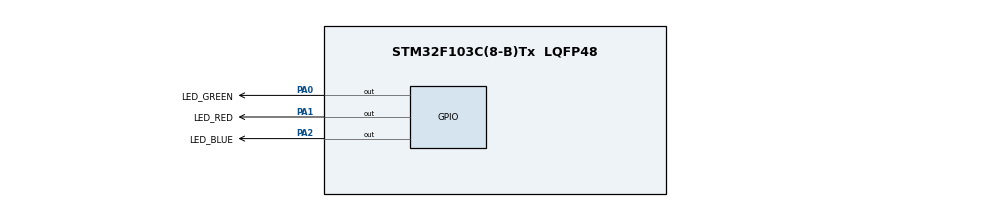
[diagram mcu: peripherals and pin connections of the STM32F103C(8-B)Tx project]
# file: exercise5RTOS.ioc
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FREERTOS.Tasks01=defaultTask,0,128,StartDefaultTask,Default,NULL,Dynamic,NULL,NULL
Mcu.Family=STM32F1
Mcu.Name=STM32F103C(8-B)Tx
Mcu.Package=LQFP48
NVIC.PriorityGroup=NVIC_PRIORITYGROUP_4
PA0-WKUP.GPIO_Label=LED_GREEN
PA0-WKUP.Signal=GPIO_Output
PA1.GPIO_Label=LED_RED
PA1.Signal=GPIO_Output
PA13.Mode=Serial_Wire
PA13.Signal=SYS_JTMS-SWDIO
PA14.Mode=Serial_Wire
PA14.Signal=SYS_JTCK-SWCLK
PA2.GPIO_Label=LED_BLUE
PA2.Signal=GPIO_Output
PD0-OSC_IN.Mode=HSE-External-Oscillator
PD0-OSC_IN.Signal=RCC_OSC_IN
PD1-OSC_OUT.Mode=HSE-External-Oscillator
PD1-OSC_OUT.Signal=RCC_OSC_OUT
ProjectManager.HeapSize=0x200
ProjectManager.StackSize=0x400
ProjectManager.TargetToolchain=STM32CubeIDE
RCC.APB1Freq_Value=8000000
RCC.APB2Freq_Value=8000000
VP_FREERTOS_VS_CMSIS_V1.Mode=CMSIS_V1
board=custom

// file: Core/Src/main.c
/* USER CODE BEGIN Header */
/**
  ******************************************************************************
  * @file           : main.c
  * @brief          : Main program body
  ******************************************************************************
  * @attention
  *
  * Copyright (c) 2024 STMicroelectronics.
  * All rights reserved.
  *
  * This software is licensed under terms that can be found in the LICENSE file
  * in the root directory of this software component.
  * If no LICENSE file comes with this software, it is provided AS-IS.
  *
  ******************************************************************************
  */
/* USER CODE END Header */
#include "main.h"
#include "cmsis_os.h"
#include "FreeRTOS.h"
#include "task.h"

volatile uint8_t startFlag = 1; // Start flag (1 = Up, 0 = Down)

osThreadId defaultTaskHandle;

void SystemClock_Config(void);
static void MX_GPIO_Init(void);
void StartDefaultTask(void const * argument);

/* USER CODE BEGIN PFP */
void taskGreenLED(void *params);
void taskRedLED(void *params);
void accessSharedData(void);

/* USER CODE END PFP */

int main(void)
{

  /* MCU Configuration--------------------------------------------------------*/

  /* Reset of all peripherals, Initializes the Flash interface and the Systick. */
  HAL_Init();

  /* Configure the system clock */
  SystemClock_Config();

  /* Initialize all configured peripherals */
  MX_GPIO_Init();

  /* Create the thread(s) */
  /* definition and creation of defaultTask */
  osThreadDef(defaultTask, StartDefaultTask, osPriorityNormal, 0, 128);
  defaultTaskHandle = osThreadCreate(osThread(defaultTask), NULL);

  /* USER CODE BEGIN RTOS_THREADS */
  // Membuat tugas untuk LED Hijau dan Merah
  xTaskCreate(taskGreenLED, "GreenLED", 128, NULL, 1, NULL);
  xTaskCreate(taskRedLED, "RedLED", 128, NULL, 2, NULL); // Prioritas lebih tinggi

  /* USER CODE END RTOS_THREADS */

  /* Start scheduler */
  osKernelStart();

  /* We should never get here as control is now taken by the scheduler */
  /* Infinite loop */
  while (1)
  {

  }
}

void SystemClock_Config(void)
{
  RCC_OscInitTypeDef RCC_OscInitStruct = {0};
  RCC_ClkInitTypeDef RCC_ClkInitStruct = {0};

  /** Initializes the RCC Oscillators according to the specified parameters
  * in the RCC_OscInitTypeDef structure.
  */
  RCC_OscInitStruct.OscillatorType = RCC_OSCILLATORTYPE_HSI;
  RCC_OscInitStruct.HSIState = RCC_HSI_ON;
  RCC_OscInitStruct.HSICalibrationValue = RCC_HSICALIBRATION_DEFAULT;
  RCC_OscInitStruct.PLL.PLLState = RCC_PLL_NONE;
  if (HAL_RCC_OscConfig(&RCC_OscInitStruct) != HAL_OK)
  {
    Error_Handler();
  }

  /** Initializes the CPU, AHB and APB buses clocks
  */
  RCC_ClkInitStruct.ClockType = RCC_CLOCKTYPE_HCLK|RCC_CLOCKTYPE_SYSCLK
                              |RCC_CLOCKTYPE_PCLK1|RCC_CLOCKTYPE_PCLK2;
  RCC_ClkInitStruct.SYSCLKSource = RCC_SYSCLKSOURCE_HSI;
  RCC_ClkInitStruct.AHBCLKDivider = RCC_SYSCLK_DIV1;
  RCC_ClkInitStruct.APB1CLKDivider = RCC_HCLK_DIV1;
  RCC_ClkInitStruct.APB2CLKDivider = RCC_HCLK_DIV1;

  if (HAL_RCC_ClockConfig(&RCC_ClkInitStruct, FLASH_LATENCY_0) != HAL_OK)
  {
    Error_Handler();
  }
}

static void MX_GPIO_Init(void)
{
  GPIO_InitTypeDef GPIO_InitStruct = {0};

  /* GPIO Ports Clock Enable */
  __HAL_RCC_GPIOD_CLK_ENABLE();
  __HAL_RCC_GPIOA_CLK_ENABLE();

  /*Configure GPIO pin Output Level */
  HAL_GPIO_WritePin(GPIOA, LED_GREEN_Pin|LED_RED_Pin|LED_BLUE_Pin, GPIO_PIN_RESET);

  /*Configure GPIO pins : LED_GREEN_Pin LED_RED_Pin LED_BLUE_Pin */
  GPIO_InitStruct.Pin = LED_GREEN_Pin|LED_RED_Pin|LED_BLUE_Pin;
  GPIO_InitStruct.Mode = GPIO_MODE_OUTPUT_PP;
  GPIO_InitStruct.Pull = GPIO_NOPULL;
  GPIO_InitStruct.Speed = GPIO_SPEED_FREQ_LOW;
  HAL_GPIO_Init(GPIOA, &GPIO_InitStruct);

}

/* USER CODE BEGIN 4 */
// Fungsi Akses Data Bersama
void accessSharedData() {
    if (startFlag == 1) {
        startFlag = 0; // Set flag ke Down
        HAL_Delay(500); // Simulasi akses (500 ms)
        startFlag = 1; // Set flag ke Up
    } else {
        HAL_GPIO_WritePin(GPIOA, GPIO_PIN_2, GPIO_PIN_SET); // Nyalakan LED biru (indikasi kontensi)
        HAL_Delay(100); // Tahan nyala LED biru agar terlihat
        HAL_GPIO_WritePin(GPIOA, GPIO_PIN_2, GPIO_PIN_RESET); // Matikan LED biru
    }
}

// Tugas LED Hijau
void taskGreenLED(void *params) {
    for (;;) {
        HAL_GPIO_WritePin(GPIOA, GPIO_PIN_0, GPIO_PIN_SET); // Nyalakan LED hijau
        accessSharedData();
        HAL_GPIO_WritePin(GPIOA, GPIO_PIN_0, GPIO_PIN_RESET); // Matikan LED hijau
        vTaskDelay(pdMS_TO_TICKS(500)); // Jeda 0.5 detik
    }
}

// Tugas LED Merah
void taskRedLED(void *params) {
    for (;;) {
        HAL_GPIO_WritePin(GPIOA, GPIO_PIN_1, GPIO_PIN_SET); // Nyalakan LED merah
        accessSharedData();
        HAL_GPIO_WritePin(GPIOA, GPIO_PIN_1, GPIO_PIN_RESET); // Matikan LED merah
        vTaskDelay(pdMS_TO_TICKS(100)); // Jeda 0.1 detik
    }
}
/* USER CODE END 4 */

void StartDefaultTask(void const * argument)
{
  for(;;)
  {
    osDelay(1);
  }
}

void Error_Handler(void)
{
  __disable_irq();
  while (1)
  {
  }
}
